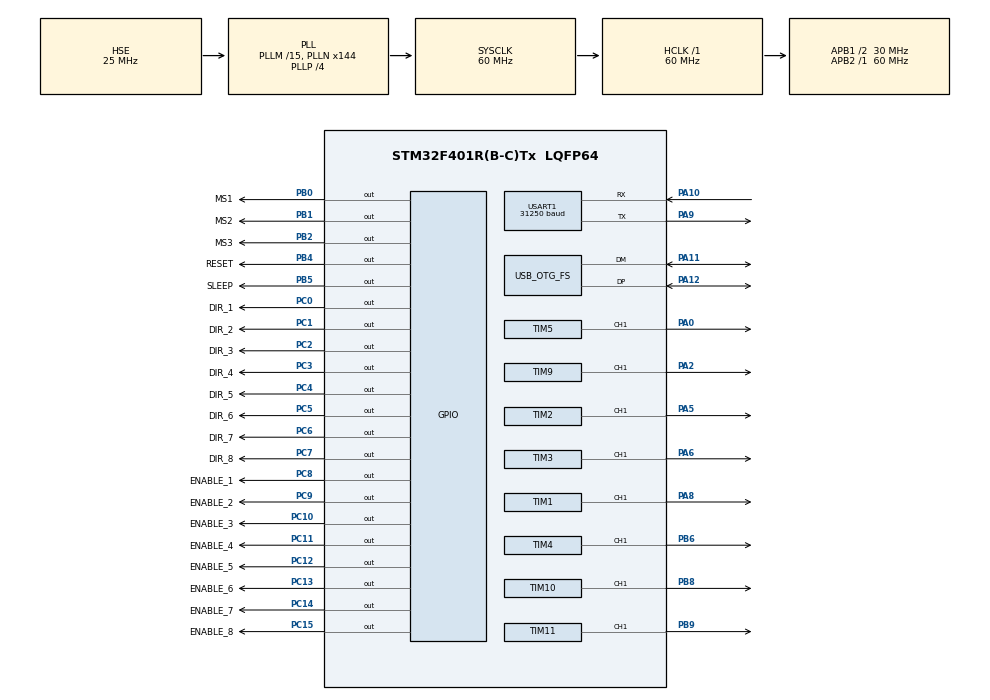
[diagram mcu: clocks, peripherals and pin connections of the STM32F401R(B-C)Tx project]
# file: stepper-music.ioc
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Mcu.Family=STM32F4
Mcu.Name=STM32F401R(B-C)Tx
Mcu.Package=LQFP64
NVIC.OTG_FS_IRQn=true\:0\:0\:false\:false\:true\:true\:true\:true
NVIC.PriorityGroup=NVIC_PRIORITYGROUP_4
NVIC.USART1_IRQn=true\:0\:0\:false\:false\:true\:true\:true\:true
PA0-WKUP.Signal=S_TIM5_CH1
PA10.Mode=Asynchronous
PA10.Signal=USART1_RX
PA11.Mode=Device_Only
PA11.Signal=USB_OTG_FS_DM
PA12.Mode=Device_Only
PA12.Signal=USB_OTG_FS_DP
PA2.Signal=S_TIM9_CH1
PA5.Signal=S_TIM2_CH1_ETR
PA6.Signal=S_TIM3_CH1
PA8.Signal=S_TIM1_CH1
PA9.Mode=Asynchronous
PA9.Signal=USART1_TX
PB0.GPIO_Label=MS1
PB0.Signal=GPIO_Output
PB1.GPIO_Label=MS2
PB1.Signal=GPIO_Output
PB2.GPIO_Label=MS3
PB2.Signal=GPIO_Output
PB4.GPIO_Label=RESET
PB4.PinState=GPIO_PIN_SET
PB4.Signal=GPIO_Output
PB5.GPIO_Label=SLEEP
PB5.PinState=GPIO_PIN_SET
PB5.Signal=GPIO_Output
PB6.Signal=S_TIM4_CH1
PB8.Signal=S_TIM10_CH1
PB9.Signal=S_TIM11_CH1
PC0.GPIO_Label=DIR_1
PC0.Signal=GPIO_Output
PC1.GPIO_Label=DIR_2
PC1.Signal=GPIO_Output
PC10.GPIO_Label=ENABLE_3
PC10.Signal=GPIO_Output
PC11.GPIO_Label=ENABLE_4
PC11.Signal=GPIO_Output
PC12.GPIO_Label=ENABLE_5
PC12.Signal=GPIO_Output
PC13-ANTI_TAMP.GPIO_Label=ENABLE_6
PC13-ANTI_TAMP.Signal=GPIO_Output
PC14-OSC32_IN.GPIO_Label=ENABLE_7
PC14-OSC32_IN.GPIO_Speed=GPIO_SPEED_FREQ_LOW
PC14-OSC32_IN.Signal=GPIO_Output
PC15-OSC32_OUT.GPIO_Label=ENABLE_8
PC15-OSC32_OUT.Signal=GPIO_Output
PC2.GPIO_Label=DIR_3
PC2.Signal=GPIO_Output
PC3.GPIO_Label=DIR_4
PC3.Signal=GPIO_Output
PC4.GPIO_Label=DIR_5
PC4.Signal=GPIO_Output
PC5.GPIO_Label=DIR_6
PC5.Signal=GPIO_Output
PC6.GPIO_Label=DIR_7
PC6.Signal=GPIO_Output
PC7.GPIO_Label=DIR_8
PC7.Signal=GPIO_Output
PC8.GPIO_Label=ENABLE_1
PC8.Signal=GPIO_Output
PC9.GPIO_Label=ENABLE_2
PC9.Signal=GPIO_Output
PH0\ -\ OSC_IN.Mode=HSE-External-Oscillator
PH0\ -\ OSC_IN.Signal=RCC_OSC_IN
PH1\ -\ OSC_OUT.Mode=HSE-External-Oscillator
PH1\ -\ OSC_OUT.Signal=RCC_OSC_OUT
ProjectManager.HeapSize=0x200
ProjectManager.StackSize=0x400
ProjectManager.TargetToolchain=STM32CubeIDE
RCC.48MHZClocksFreq_Value=48000000
RCC.AHBFreq_Value=60000000
RCC.APB1CLKDivider=RCC_HCLK_DIV2
RCC.APB1Freq_Value=30000000
RCC.APB1TimFreq_Value=60000000
RCC.APB2Freq_Value=60000000
RCC.APB2TimFreq_Value=60000000
RCC.CortexFreq_Value=60000000
RCC.HCLKFreq_Value=60000000
RCC.HSE_VALUE=25000000
RCC.HSI_VALUE=16000000
RCC.LSE_VALUE=32768
RCC.PLLM=15
RCC.PLLN=144
RCC.PLLP=RCC_PLLP_DIV4
RCC.PLLQ=5
RCC.SYSCLKFreq_VALUE=60000000
RCC.SYSCLKSource=RCC_SYSCLKSOURCE_PLLCLK
RCC.VCOOutputFreq_Value=240000000
SH.S_TIM10_CH1.0=TIM10_CH1,PWM Generation1 CH1
SH.S_TIM11_CH1.0=TIM11_CH1,PWM Generation1 CH1
SH.S_TIM1_CH1.0=TIM1_CH1,PWM Generation1 CH1
SH.S_TIM2_CH1_ETR.0=TIM2_CH1,PWM Generation1 CH1
SH.S_TIM3_CH1.0=TIM3_CH1,PWM Generation1 CH1
SH.S_TIM4_CH1.0=TIM4_CH1,PWM Generation1 CH1
SH.S_TIM5_CH1.0=TIM5_CH1,PWM Generation1 CH1
SH.S_TIM9_CH1.0=TIM9_CH1,PWM Generation1 CH1
TIM1.AutoReloadPreload=TIM_AUTORELOAD_PRELOAD_ENABLE
TIM1.Channel-PWM\ Generation1\ CH1=TIM_CHANNEL_1
TIM1.Prescaler=60
TIM10.AutoReloadPreload=TIM_AUTORELOAD_PRELOAD_ENABLE
TIM10.Channel=TIM_CHANNEL_1
TIM10.Prescaler=60
TIM11.AutoReloadPreload=TIM_AUTORELOAD_PRELOAD_ENABLE
TIM11.Channel=TIM_CHANNEL_1
TIM11.Prescaler=60
TIM2.AutoReloadPreload=TIM_AUTORELOAD_PRELOAD_ENABLE
TIM2.Channel-PWM\ Generation1\ CH1=TIM_CHANNEL_1
TIM2.Period=65535
TIM2.Prescaler=60
TIM3.AutoReloadPreload=TIM_AUTORELOAD_PRELOAD_ENABLE
TIM3.Channel-PWM\ Generation1\ CH1=TIM_CHANNEL_1
TIM3.Prescaler=60
TIM4.AutoReloadPreload=TIM_AUTORELOAD_PRELOAD_ENABLE
TIM4.Channel-PWM\ Generation1\ CH1=TIM_CHANNEL_1
TIM4.Prescaler=60
TIM5.AutoReloadPreload=TIM_AUTORELOAD_PRELOAD_ENABLE
TIM5.Channel-PWM\ Generation1\ CH1=TIM_CHANNEL_1
TIM5.Prescaler=60
TIM9.AutoReloadPreload=TIM_AUTORELOAD_PRELOAD_ENABLE
TIM9.Channel-PWM\ Generation1\ CH1=TIM_CHANNEL_1
TIM9.Prescaler=60
USART1.BaudRate=31250
USART1.Mode=MODE_RX
USART1.VirtualMode=VM_ASYNC
USB_OTG_FS.VirtualMode=Device_Only
VP_TIM10_VS_ClockSourceINT.Mode=Enable_Timer
VP_TIM11_VS_ClockSourceINT.Mode=Enable_Timer
board=custom

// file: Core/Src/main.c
/* USER CODE BEGIN Header */
/**
  ******************************************************************************
  * @file           : main.c
  * @brief          : Main program body
  ******************************************************************************
  * @attention
  *
  * Copyright (c) 2026 STMicroelectronics.
  * All rights reserved.
  *
  * This software is licensed under terms that can be found in the LICENSE file
  * in the root directory of this software component.
  * If no LICENSE file comes with this software, it is provided AS-IS.
  *
  ******************************************************************************
  */
/* USER CODE END Header */
#include "main.h"

/* USER CODE BEGIN Includes */
#include <stdio.h>
#include "midi.h"
/* USER CODE END Includes */

TIM_HandleTypeDef htim1;
TIM_HandleTypeDef htim2;
TIM_HandleTypeDef htim3;
TIM_HandleTypeDef htim4;
TIM_HandleTypeDef htim5;
TIM_HandleTypeDef htim9;
TIM_HandleTypeDef htim10;
TIM_HandleTypeDef htim11;

UART_HandleTypeDef huart1;

PCD_HandleTypeDef hpcd_USB_OTG_FS;

void SystemClock_Config(void);
static void MX_GPIO_Init(void);
static void MX_TIM1_Init(void);
static void MX_TIM2_Init(void);
static void MX_TIM3_Init(void);
static void MX_TIM4_Init(void);
static void MX_TIM5_Init(void);
static void MX_TIM9_Init(void);
static void MX_TIM10_Init(void);
static void MX_TIM11_Init(void);
static void MX_USB_OTG_FS_PCD_Init(void);
static void MX_USART1_UART_Init(void);

int main(void)
{

  /* MCU Configuration--------------------------------------------------------*/

  /* Reset of all peripherals, Initializes the Flash interface and the Systick. */
  HAL_Init();

  /* Configure the system clock */
  SystemClock_Config();

  /* Initialize all configured peripherals */
  MX_GPIO_Init();
  MX_TIM1_Init();
  MX_TIM2_Init();
  MX_TIM3_Init();
  MX_TIM4_Init();
  MX_TIM5_Init();
  MX_TIM9_Init();
  MX_TIM10_Init();
  MX_TIM11_Init();
  MX_USB_OTG_FS_PCD_Init();
  MX_USART1_UART_Init();
  /* USER CODE BEGIN 2 */
  setup();
//  printf("Hello, World!");

  /* USER CODE END 2 */

  /* Infinite loop */
  while (1)
  {

    /* USER CODE BEGIN 3 */
	loop();
  }
  /* USER CODE END 3 */
}

void SystemClock_Config(void)
{
  RCC_OscInitTypeDef RCC_OscInitStruct = {0};
  RCC_ClkInitTypeDef RCC_ClkInitStruct = {0};

  /** Configure the main internal regulator output voltage
  */
  __HAL_RCC_PWR_CLK_ENABLE();
  __HAL_PWR_VOLTAGESCALING_CONFIG(PWR_REGULATOR_VOLTAGE_SCALE2);

  /** Initializes the RCC Oscillators according to the specified parameters
  * in the RCC_OscInitTypeDef structure.
  */
  RCC_OscInitStruct.OscillatorType = RCC_OSCILLATORTYPE_HSE;
  RCC_OscInitStruct.HSEState = RCC_HSE_ON;
  RCC_OscInitStruct.PLL.PLLState = RCC_PLL_ON;
  RCC_OscInitStruct.PLL.PLLSource = RCC_PLLSOURCE_HSE;
  RCC_OscInitStruct.PLL.PLLM = 15;
  RCC_OscInitStruct.PLL.PLLN = 144;
  RCC_OscInitStruct.PLL.PLLP = RCC_PLLP_DIV4;
  RCC_OscInitStruct.PLL.PLLQ = 5;
  if (HAL_RCC_OscConfig(&RCC_OscInitStruct) != HAL_OK)
  {
    Error_Handler();
  }

  /** Initializes the CPU, AHB and APB buses clocks
  */
  RCC_ClkInitStruct.ClockType = RCC_CLOCKTYPE_HCLK|RCC_CLOCKTYPE_SYSCLK
                              |RCC_CLOCKTYPE_PCLK1|RCC_CLOCKTYPE_PCLK2;
  RCC_ClkInitStruct.SYSCLKSource = RCC_SYSCLKSOURCE_PLLCLK;
  RCC_ClkInitStruct.AHBCLKDivider = RCC_SYSCLK_DIV1;
  RCC_ClkInitStruct.APB1CLKDivider = RCC_HCLK_DIV2;
  RCC_ClkInitStruct.APB2CLKDivider = RCC_HCLK_DIV1;

  if (HAL_RCC_ClockConfig(&RCC_ClkInitStruct, FLASH_LATENCY_1) != HAL_OK)
  {
    Error_Handler();
  }
}

static void MX_TIM1_Init(void)
{

  TIM_MasterConfigTypeDef sMasterConfig = {0};
  TIM_OC_InitTypeDef sConfigOC = {0};
  TIM_BreakDeadTimeConfigTypeDef sBreakDeadTimeConfig = {0};

  htim1.Instance = TIM1;
  htim1.Init.Prescaler = 60;
  htim1.Init.CounterMode = TIM_COUNTERMODE_UP;
  htim1.Init.Period = 65535;
  htim1.Init.ClockDivision = TIM_CLOCKDIVISION_DIV1;
  htim1.Init.RepetitionCounter = 0;
  htim1.Init.AutoReloadPreload = TIM_AUTORELOAD_PRELOAD_ENABLE;
  if (HAL_TIM_PWM_Init(&htim1) != HAL_OK)
  {
    Error_Handler();
  }
  sMasterConfig.MasterOutputTrigger = TIM_TRGO_RESET;
  sMasterConfig.MasterSlaveMode = TIM_MASTERSLAVEMODE_DISABLE;
  if (HAL_TIMEx_MasterConfigSynchronization(&htim1, &sMasterConfig) != HAL_OK)
  {
    Error_Handler();
  }
  sConfigOC.OCMode = TIM_OCMODE_PWM1;
  sConfigOC.Pulse = 0;
  sConfigOC.OCPolarity = TIM_OCPOLARITY_HIGH;
  sConfigOC.OCNPolarity = TIM_OCNPOLARITY_HIGH;
  sConfigOC.OCFastMode = TIM_OCFAST_DISABLE;
  sConfigOC.OCIdleState = TIM_OCIDLESTATE_RESET;
  sConfigOC.OCNIdleState = TIM_OCNIDLESTATE_RESET;
  if (HAL_TIM_PWM_ConfigChannel(&htim1, &sConfigOC, TIM_CHANNEL_1) != HAL_OK)
  {
    Error_Handler();
  }
  sBreakDeadTimeConfig.OffStateRunMode = TIM_OSSR_DISABLE;
  sBreakDeadTimeConfig.OffStateIDLEMode = TIM_OSSI_DISABLE;
  sBreakDeadTimeConfig.LockLevel = TIM_LOCKLEVEL_OFF;
  sBreakDeadTimeConfig.DeadTime = 0;
  sBreakDeadTimeConfig.BreakState = TIM_BREAK_DISABLE;
  sBreakDeadTimeConfig.BreakPolarity = TIM_BREAKPOLARITY_HIGH;
  sBreakDeadTimeConfig.AutomaticOutput = TIM_AUTOMATICOUTPUT_DISABLE;
  if (HAL_TIMEx_ConfigBreakDeadTime(&htim1, &sBreakDeadTimeConfig) != HAL_OK)
  {
    Error_Handler();
  }
  HAL_TIM_MspPostInit(&htim1);

}

static void MX_TIM2_Init(void)
{

  TIM_MasterConfigTypeDef sMasterConfig = {0};
  TIM_OC_InitTypeDef sConfigOC = {0};

  htim2.Instance = TIM2;
  htim2.Init.Prescaler = 60;
  htim2.Init.CounterMode = TIM_COUNTERMODE_UP;
  htim2.Init.Period = 65535;
  htim2.Init.ClockDivision = TIM_CLOCKDIVISION_DIV1;
  htim2.Init.AutoReloadPreload = TIM_AUTORELOAD_PRELOAD_ENABLE;
  if (HAL_TIM_PWM_Init(&htim2) != HAL_OK)
  {
    Error_Handler();
  }
  sMasterConfig.MasterOutputTrigger = TIM_TRGO_RESET;
  sMasterConfig.MasterSlaveMode = TIM_MASTERSLAVEMODE_DISABLE;
  if (HAL_TIMEx_MasterConfigSynchronization(&htim2, &sMasterConfig) != HAL_OK)
  {
    Error_Handler();
  }
  sConfigOC.OCMode = TIM_OCMODE_PWM1;
  sConfigOC.Pulse = 0;
  sConfigOC.OCPolarity = TIM_OCPOLARITY_HIGH;
  sConfigOC.OCFastMode = TIM_OCFAST_DISABLE;
  if (HAL_TIM_PWM_ConfigChannel(&htim2, &sConfigOC, TIM_CHANNEL_1) != HAL_OK)
  {
    Error_Handler();
  }
  HAL_TIM_MspPostInit(&htim2);

}

static void MX_TIM3_Init(void)
{

  TIM_MasterConfigTypeDef sMasterConfig = {0};
  TIM_OC_InitTypeDef sConfigOC = {0};

  htim3.Instance = TIM3;
  htim3.Init.Prescaler = 60;
  htim3.Init.CounterMode = TIM_COUNTERMODE_UP;
  htim3.Init.Period = 65535;
  htim3.Init.ClockDivision = TIM_CLOCKDIVISION_DIV1;
  htim3.Init.AutoReloadPreload = TIM_AUTORELOAD_PRELOAD_ENABLE;
  if (HAL_TIM_PWM_Init(&htim3) != HAL_OK)
  {
    Error_Handler();
  }
  sMasterConfig.MasterOutputTrigger = TIM_TRGO_RESET;
  sMasterConfig.MasterSlaveMode = TIM_MASTERSLAVEMODE_DISABLE;
  if (HAL_TIMEx_MasterConfigSynchronization(&htim3, &sMasterConfig) != HAL_OK)
  {
    Error_Handler();
  }
  sConfigOC.OCMode = TIM_OCMODE_PWM1;
  sConfigOC.Pulse = 0;
  sConfigOC.OCPolarity = TIM_OCPOLARITY_HIGH;
  sConfigOC.OCFastMode = TIM_OCFAST_DISABLE;
  if (HAL_TIM_PWM_ConfigChannel(&htim3, &sConfigOC, TIM_CHANNEL_1) != HAL_OK)
  {
    Error_Handler();
  }
  HAL_TIM_MspPostInit(&htim3);

}

static void MX_TIM4_Init(void)
{

  TIM_MasterConfigTypeDef sMasterConfig = {0};
  TIM_OC_InitTypeDef sConfigOC = {0};

  htim4.Instance = TIM4;
  htim4.Init.Prescaler = 60;
  htim4.Init.CounterMode = TIM_COUNTERMODE_UP;
  htim4.Init.Period = 65535;
  htim4.Init.ClockDivision = TIM_CLOCKDIVISION_DIV1;
  htim4.Init.AutoReloadPreload = TIM_AUTORELOAD_PRELOAD_ENABLE;
  if (HAL_TIM_PWM_Init(&htim4) != HAL_OK)
  {
    Error_Handler();
  }
  sMasterConfig.MasterOutputTrigger = TIM_TRGO_RESET;
  sMasterConfig.MasterSlaveMode = TIM_MASTERSLAVEMODE_DISABLE;
  if (HAL_TIMEx_MasterConfigSynchronization(&htim4, &sMasterConfig) != HAL_OK)
  {
    Error_Handler();
  }
  sConfigOC.OCMode = TIM_OCMODE_PWM1;
  sConfigOC.Pulse = 0;
  sConfigOC.OCPolarity = TIM_OCPOLARITY_HIGH;
  sConfigOC.OCFastMode = TIM_OCFAST_DISABLE;
  if (HAL_TIM_PWM_ConfigChannel(&htim4, &sConfigOC, TIM_CHANNEL_1) != HAL_OK)
  {
    Error_Handler();
  }
  HAL_TIM_MspPostInit(&htim4);

}

static void MX_TIM5_Init(void)
{

  TIM_MasterConfigTypeDef sMasterConfig = {0};
  TIM_OC_InitTypeDef sConfigOC = {0};

  htim5.Instance = TIM5;
  htim5.Init.Prescaler = 60;
  htim5.Init.CounterMode = TIM_COUNTERMODE_UP;
  htim5.Init.Period = 4294967295;
  htim5.Init.ClockDivision = TIM_CLOCKDIVISION_DIV1;
  htim5.Init.AutoReloadPreload = TIM_AUTORELOAD_PRELOAD_ENABLE;
  if (HAL_TIM_PWM_Init(&htim5) != HAL_OK)
  {
    Error_Handler();
  }
  sMasterConfig.MasterOutputTrigger = TIM_TRGO_RESET;
  sMasterConfig.MasterSlaveMode = TIM_MASTERSLAVEMODE_DISABLE;
  if (HAL_TIMEx_MasterConfigSynchronization(&htim5, &sMasterConfig) != HAL_OK)
  {
    Error_Handler();
  }
  sConfigOC.OCMode = TIM_OCMODE_PWM1;
  sConfigOC.Pulse = 0;
  sConfigOC.OCPolarity = TIM_OCPOLARITY_HIGH;
  sConfigOC.OCFastMode = TIM_OCFAST_DISABLE;
  if (HAL_TIM_PWM_ConfigChannel(&htim5, &sConfigOC, TIM_CHANNEL_1) != HAL_OK)
  {
    Error_Handler();
  }
  HAL_TIM_MspPostInit(&htim5);

}

static void MX_TIM9_Init(void)
{

  TIM_OC_InitTypeDef sConfigOC = {0};

  htim9.Instance = TIM9;
  htim9.Init.Prescaler = 60;
  htim9.Init.CounterMode = TIM_COUNTERMODE_UP;
  htim9.Init.Period = 65535;
  htim9.Init.ClockDivision = TIM_CLOCKDIVISION_DIV1;
  htim9.Init.AutoReloadPreload = TIM_AUTORELOAD_PRELOAD_ENABLE;
  if (HAL_TIM_PWM_Init(&htim9) != HAL_OK)
  {
    Error_Handler();
  }
  sConfigOC.OCMode = TIM_OCMODE_PWM1;
  sConfigOC.Pulse = 0;
  sConfigOC.OCPolarity = TIM_OCPOLARITY_HIGH;
  sConfigOC.OCFastMode = TIM_OCFAST_DISABLE;
  if (HAL_TIM_PWM_ConfigChannel(&htim9, &sConfigOC, TIM_CHANNEL_1) != HAL_OK)
  {
    Error_Handler();
  }
  HAL_TIM_MspPostInit(&htim9);

}

static void MX_TIM10_Init(void)
{

  TIM_OC_InitTypeDef sConfigOC = {0};

  htim10.Instance = TIM10;
  htim10.Init.Prescaler = 60;
  htim10.Init.CounterMode = TIM_COUNTERMODE_UP;
  htim10.Init.Period = 65535;
  htim10.Init.ClockDivision = TIM_CLOCKDIVISION_DIV1;
  htim10.Init.AutoReloadPreload = TIM_AUTORELOAD_PRELOAD_ENABLE;
  if (HAL_TIM_Base_Init(&htim10) != HAL_OK)
  {
    Error_Handler();
  }
  if (HAL_TIM_PWM_Init(&htim10) != HAL_OK)
  {
    Error_Handler();
  }
  sConfigOC.OCMode = TIM_OCMODE_PWM1;
  sConfigOC.Pulse = 0;
  sConfigOC.OCPolarity = TIM_OCPOLARITY_HIGH;
  sConfigOC.OCFastMode = TIM_OCFAST_DISABLE;
  if (HAL_TIM_PWM_ConfigChannel(&htim10, &sConfigOC, TIM_CHANNEL_1) != HAL_OK)
  {
    Error_Handler();
  }
  HAL_TIM_MspPostInit(&htim10);

}

static void MX_TIM11_Init(void)
{

  TIM_OC_InitTypeDef sConfigOC = {0};

  htim11.Instance = TIM11;
  htim11.Init.Prescaler = 60;
  htim11.Init.CounterMode = TIM_COUNTERMODE_UP;
  htim11.Init.Period = 65535;
  htim11.Init.ClockDivision = TIM_CLOCKDIVISION_DIV1;
  htim11.Init.AutoReloadPreload = TIM_AUTORELOAD_PRELOAD_ENABLE;
  if (HAL_TIM_Base_Init(&htim11) != HAL_OK)
  {
    Error_Handler();
  }
  if (HAL_TIM_PWM_Init(&htim11) != HAL_OK)
  {
    Error_Handler();
  }
  sConfigOC.OCMode = TIM_OCMODE_PWM1;
  sConfigOC.Pulse = 0;
  sConfigOC.OCPolarity = TIM_OCPOLARITY_HIGH;
  sConfigOC.OCFastMode = TIM_OCFAST_DISABLE;
  if (HAL_TIM_PWM_ConfigChannel(&htim11, &sConfigOC, TIM_CHANNEL_1) != HAL_OK)
  {
    Error_Handler();
  }
  HAL_TIM_MspPostInit(&htim11);

}

static void MX_USART1_UART_Init(void)
{

  huart1.Instance = USART1;
  huart1.Init.BaudRate = 31250;
  huart1.Init.WordLength = UART_WORDLENGTH_8B;
  huart1.Init.StopBits = UART_STOPBITS_1;
  huart1.Init.Parity = UART_PARITY_NONE;
  huart1.Init.Mode = UART_MODE_RX;
  huart1.Init.HwFlowCtl = UART_HWCONTROL_NONE;
  huart1.Init.OverSampling = UART_OVERSAMPLING_16;
  if (HAL_UART_Init(&huart1) != HAL_OK)
  {
    Error_Handler();
  }

}

static void MX_USB_OTG_FS_PCD_Init(void)
{

  hpcd_USB_OTG_FS.Instance = USB_OTG_FS;
  hpcd_USB_OTG_FS.Init.dev_endpoints = 4;
  hpcd_USB_OTG_FS.Init.speed = PCD_SPEED_FULL;
  hpcd_USB_OTG_FS.Init.dma_enable = DISABLE;
  hpcd_USB_OTG_FS.Init.phy_itface = PCD_PHY_EMBEDDED;
  hpcd_USB_OTG_FS.Init.Sof_enable = DISABLE;
  hpcd_USB_OTG_FS.Init.low_power_enable = DISABLE;
  hpcd_USB_OTG_FS.Init.lpm_enable = DISABLE;
  hpcd_USB_OTG_FS.Init.vbus_sensing_enable = DISABLE;
  hpcd_USB_OTG_FS.Init.use_dedicated_ep1 = DISABLE;
  if (HAL_PCD_Init(&hpcd_USB_OTG_FS) != HAL_OK)
  {
    Error_Handler();
  }

}

static void MX_GPIO_Init(void)
{
  GPIO_InitTypeDef GPIO_InitStruct = {0};

  /* GPIO Ports Clock Enable */
  __HAL_RCC_GPIOC_CLK_ENABLE();
  __HAL_RCC_GPIOH_CLK_ENABLE();
  __HAL_RCC_GPIOA_CLK_ENABLE();
  __HAL_RCC_GPIOB_CLK_ENABLE();

  /*Configure GPIO pin Output Level */
  HAL_GPIO_WritePin(GPIOC, ENABLE_6_Pin|ENABLE_7_Pin|ENABLE_8_Pin|DIR_1_Pin
                          |DIR_2_Pin|DIR_3_Pin|DIR_4_Pin|DIR_5_Pin
                          |DIR_6_Pin|DIR_7_Pin|DIR_8_Pin|ENABLE_1_Pin
                          |ENABLE_2_Pin|ENABLE_3_Pin|ENABLE_4_Pin|ENABLE_5_Pin, GPIO_PIN_RESET);

  /*Configure GPIO pin Output Level */
  HAL_GPIO_WritePin(GPIOB, MS1_Pin|MS2_Pin|MS3_Pin, GPIO_PIN_RESET);

  /*Configure GPIO pin Output Level */
  HAL_GPIO_WritePin(GPIOB, RESET_Pin|SLEEP_Pin, GPIO_PIN_SET);

  /*Configure GPIO pins : ENABLE_6_Pin ENABLE_7_Pin ENABLE_8_Pin DIR_1_Pin
                           DIR_2_Pin DIR_3_Pin DIR_4_Pin DIR_5_Pin
                           DIR_6_Pin DIR_7_Pin DIR_8_Pin ENABLE_1_Pin
                           ENABLE_2_Pin ENABLE_3_Pin ENABLE_4_Pin ENABLE_5_Pin */
  GPIO_InitStruct.Pin = ENABLE_6_Pin|ENABLE_7_Pin|ENABLE_8_Pin|DIR_1_Pin
                          |DIR_2_Pin|DIR_3_Pin|DIR_4_Pin|DIR_5_Pin
                          |DIR_6_Pin|DIR_7_Pin|DIR_8_Pin|ENABLE_1_Pin
                          |ENABLE_2_Pin|ENABLE_3_Pin|ENABLE_4_Pin|ENABLE_5_Pin;
  GPIO_InitStruct.Mode = GPIO_MODE_OUTPUT_PP;
  GPIO_InitStruct.Pull = GPIO_NOPULL;
  GPIO_InitStruct.Speed = GPIO_SPEED_FREQ_LOW;
  HAL_GPIO_Init(GPIOC, &GPIO_InitStruct);

  /*Configure GPIO pins : MS1_Pin MS2_Pin MS3_Pin RESET_Pin
                           SLEEP_Pin */
  GPIO_InitStruct.Pin = MS1_Pin|MS2_Pin|MS3_Pin|RESET_Pin
                          |SLEEP_Pin;
  GPIO_InitStruct.Mode = GPIO_MODE_OUTPUT_PP;
  GPIO_InitStruct.Pull = GPIO_NOPULL;
  GPIO_InitStruct.Speed = GPIO_SPEED_FREQ_LOW;
  HAL_GPIO_Init(GPIOB, &GPIO_InitStruct);

}

void Error_Handler(void)
{
  __disable_irq();
  while (1)
  {
  }
}
